# K32W041AM register map
Vendor: nxp.com; File version: 1.0
CPU: CM4 r0p1, little endian, MPU, no FPU, VTOR, 3 interrupt priority bits
Registers are 32-bit, read-write, reset 0x0 unless marked. A register's access mark holds for its fields unless they carry their own. Offsets are from the block's base; [hi:lo] are bit positions; lines under a group give offsets from that group; {n}, {i} and the like mark numbered series.

## DMIC0 — This is the description of component dmic It is General Purpose I/O with APB bus interface. More details will follow.
Base 0x4008A000
{0x0+0x100*i} CHANNEL[{i}] (i=0..1) group
  0x00 OSR — Oversample Rate register 0. This register selects the oversample rate (CIC decimation rate) for the input channel.
    [7:0] OSR — Selects the oversample rate for the related input channel.
  0x04 DIVHFCLK — DMIC Clock Register 0. This register controls the clock pre-divider for the input channel.
    [3:0] PDMDIV — PDM clock divider value. 0: divide by 1; 1: divide by 2; 2: divide by 3; 3: divide by 4; 4: divide by 6; 5: divide by 8; 6: divide by 12; 7: divide by 16; 8: divide by 24; 9: divide by 32; 10: divide by 48; 11: divide by 64; 12: divide by 96; 13: divide by 128; others = reserved.
  0x08 PREAC2FSCOEF — Pre-Emphasis Filter Coefficient for 2 FS register 0. This register seclects the pre-emphasis filter coeffcient for the input channel when 2 FS mode is used.
    [1:0] COMP — Pre-emphasis filer coefficient for 2 FS mode. 0: Compensation = 0 1: Compensation = -0.16 2: Compensation = -0.15 3: Compensation = -0.13
  0x0C PREAC4FSCOEF — Pre-Emphasis Filter Coefficient for 4 FS register 0. This register seclects the pre-emphasis filter coeffcient for the input channel when 4FS mode is used
    [1:0] COMP — Pre-emphasis filer coefficient for 4 FS mode. 0: Compensation = 0; 1: Compensation = -0.16; 2: Compensation = -0.15; 3: Compensation = -0.13.
  0x10 GAINSHIFT — Decimator Gain Shift register 0. This register adjusts the gain of the 4FS PCM data from the input filter.
    [5:0] GAIN — Gain control, as a positive or negative (two s complement) number of bits to shift.
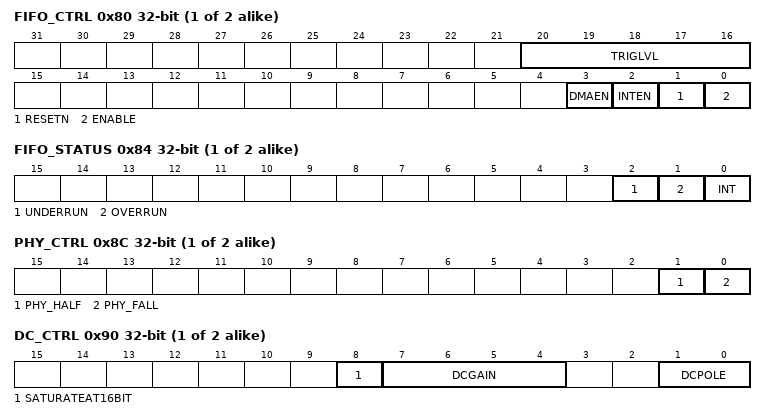
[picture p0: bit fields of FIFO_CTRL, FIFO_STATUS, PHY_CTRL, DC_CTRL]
  0x80 FIFO_CTRL — FIFO Control register 0. This register configures FIFO usage.
    [20:16] TRIGLVL — FIFO trigger level. Selects the data trigger level for interrupt or DMA operation. If enabled to do so, the FIFO level can wake up the device. 0: trigger when the FIFO has received one entry (is no longer empty). 1: trigger when the FIFO has received two entries. 15: trigger when the FIFO has received 16 entries (has become full).
    [3] DMAEN — DMA enable. 0: DMA requests are not enabled. 1: DMA requests based on FIFO level are enabled.
    [2] INTEN — Interrupt enable. 0: FIFO level interrupts are not enabled. 1: FIFO level interrupts are enabled.
    [1] RESETN — FIFO reset. 0: Reset the FIFO. This bit must be cleared before resuming operation. 1: Normal operation.
    [0] ENABLE — FIFO enable. 0: FIFO is not enabled. Enabling a DMIC channel with the FIFO disabled could be useful in order to avoid a filter settling. delay when a channel is re-enabled after a period when the data was not needed. 1: FIFO is enabled. The FIFO must be enabled in order for the CPU or DMA to read data from the DMIC via the FIFODATA register.
  0x84 FIFO_STATUS — FIFO Status register 0 . This register provides status information for the FIFO and also indicates an interrupt from the peripheral funcion.
    [2] UNDERRUN — Underrun flag. Indicates that a FIFO underflow has occurred at some point. Writing a one to this bit clears the flag.
    [1] OVERRUN — Overrun flag. Indicates that a FIFO overflow has occurred at some point. Writing a one to this bit clears the flag. This flag does not cause an interrupt.
    [0] INT — Interrupt flag. Asserted when FIFO data reaches the level specified in the FIFOCTRL register. Writing a one to this bit clears the flag. Remark: note that the bus clock to the DMIC subsystem must be running in order for an interrupt to occur.
  0x88 FIFO_DATA — FIFO Data Register 0. This register is used to read values that have been received via the PDM stream.
    [23:0] DATA — Data from the top of the input filter FIFO.
  0x8C PHY_CTRL — PHY Control / PDM Source Configuration register 0. This register configures how the PDM source signals are interpreted.
    [1] PHY_HALF — Half rate sampling. 0: Standard half rate sampling. The clock to the DMIC is sent at the same rate as the decimator is providing. 1: Use half rate sampling. The PDM clock to DMIC is divided by 2. Each PDM data is sampled twice into the decimator. The purpose of this mode is to allow slower sampling rate in quiet periods of listening for a trigger. Allowing the decimator to maintain the same decimation rate between the higher quality, higher PDM clock rate and the lower quality lower PDM clock rate means that the user can quickly switch to higher quality without re-configuring the decimator, and thus avoiding long filter settling times, when switching to higher quality (higher freq PDM clock) for recognition.
    [0] PHY_FALL — Capture PDM_DATA. 0: Capture PDM_DATA on the rising edge of PDM_CLK. 1: Capture PDM_DATA on the falling edge of PDM_CLK.
  0x90 DC_CTRL — DC Control register 0. This register controls the DC filter.
    [8] SATURATEAT16BIT — Selects 16-bit saturation. 0:Results roll over if out range and do not saturate. 1:If the result overflows, it saturates at 0xFFFF for positive overflow and 0x8000 for negative overflow.
    [7:4] DCGAIN — Fine gain adjustment in the form of a number of bits to downshift.
    [1:0] DCPOLE — DC block filter. 0: Flat response, no filter. 1: 155 Hz. 2: 78 Hz. 3: 39 Hz. These frequencies assume a PCM output frequency of 16 MHz. If the actual PCM output frequency is 8 MHz, for example, the noted frequencies would be divided by 2.
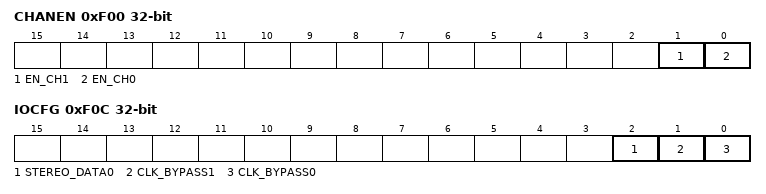
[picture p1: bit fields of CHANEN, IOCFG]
0xF00 CHANEN — Channel Enable register. This register allows enabling either or both PDM channels.
  [1] EN_CH1 — Enable channel 1. When 1, PDM channel 1 is enabled.
  [0] EN_CH0 — Enable channel 0. When 1, PDM channel 0 is enabled.
0xF0C IOCFG — I/O Configuration register. This register configures the use of the PDM pins.
  [2] STEREO_DATA0 — Stereo PDM select. When 1, PDM_DATA0 is routed to both PDM channels in a configuration that supports a single stereo digital microphone.
  [1] CLK_BYPASS1 — Bypass CLK1. When 1, PDM_DATA1 becomes the clock for PDM channel 1. This provides for the possibility of an external codec taking over the PDM bus.
  [0] CLK_BYPASS0 — Bypass CLK0. When 1, PDM_DATA1 becomes the clock for PDM channel 0. This provides for the possibility of an external codec taking over the PDM bus.
0xF10 USE2FS — Use 2FS register. This register allow selecting 2FS output rather than 1FS output.
  [0] USE2FS — Use 2FS register. 0: Use 1FS output for PCM data. 1: Use 2FS output for PCM data.
0xF80 HWVADGAIN reset 0x5 — HWVAD input gain register. This register controls the input gain of the HWVAD.
  [3:0] INPUTGAIN — Shift value for input bits. 0x0: -10 bits; 0x1: -8 bits; 0x2: -6 bits; 0x3: -4 bits; 0x4: -2 bits; 0x5: 0 bits (default); 0x6: +2 bits; 0x7: +4 bits; 0x8: +6 bits; 0x9: +8 bits; 0xA: +10 bits; 0xB: +12 bits; 0xC: +14 bits; 0xD to 0xF: Reserved.
0xF84 HWVADHPFS reset 0x1 — HWVAD filter control register. This register controls the HWVAD filter setting.
  [1:0] HPFS — High pass filter. 0: First filter by-pass; 1: High pass filter with -3dB cut-off at 1750Hz; 2: High pass filter with -3dB cut-off at 215Hz.; 3: Reserved. This filter setting parameter can be used to optimize performance for different background noise situations. In order to find the best setting, software needs to perform a rough spectral analysis of the audio signal. Rule of thumb: If the amount of low-frequency content in the background noise is small, then set HPFS=0x2, otherwise use 0x1.
0xF88 HWVADST10 — HWVAD control register. This register controls the operation of the filter block and resets the internal interrut flag.
  [0] ST10 — ST10. Once the HWVAD has triggered an interrupt, a short '1' pulse on bit ST10 clears the interrupt. Alternatively, keeping the bit on '1' level for some time has a special function for filter convergence. 0: Normal operation, waiting for HWVAD trigger event (stage 0). 1: Reset internal interrupt flag by writing a 1 pulse.
0xF8C HWVADRSTT — HWVAD filter reset register
  [0] RSTT — HWVAD filter reset. Writing a 1, then writing a '0' resets all filter values. 0: Filters anr not held in reset. 1: Holds the filters in reset.
0xF90 HWVADTHGN — HWVAD noise estimator gain register
  [3:0] THGN — Gain value for the noise estimator. Values 0 to 14. 0 corresponds to a gain of 1. THGN and THGS are used within the hardware to determine when to assert the HWVAD result.
0xF94 HWVADTHGS reset 0x4 — HWVAD signal estimator gain register
  [3:0] THGS — Gain value for the signal estimator. Values 0 to 14. 0 corresponds to a gain of 1. THGN and THGS are used within the hardware to determine when to assert the HWVAD result.
0xF98 HWVADLOWZ ro — HWVAD noise envelope estimator register
  [15:0] LOWZ — Noise envelope estimator value. This register contains 2 bytes of the output of filter stage z7. It can be used as an indication for the noise floor and must be evaluated by software. Note: For power saving reasons this register is not synchronized to the AHB bus clock domain. To ensure correct data is read, the register should be read twice. If the data is the same, then the data is correct, if not, the register should be read one more time. The noise floor is a slowly moving calculation, so several reads in a row can guarantee that register value being read can be assured to not be in the middle of a transition.
0xFFC ID ro reset 0x2 — Module Identification register
  [31:0] ID — Indicates module ID and the number of channels in this DMIC interface.
